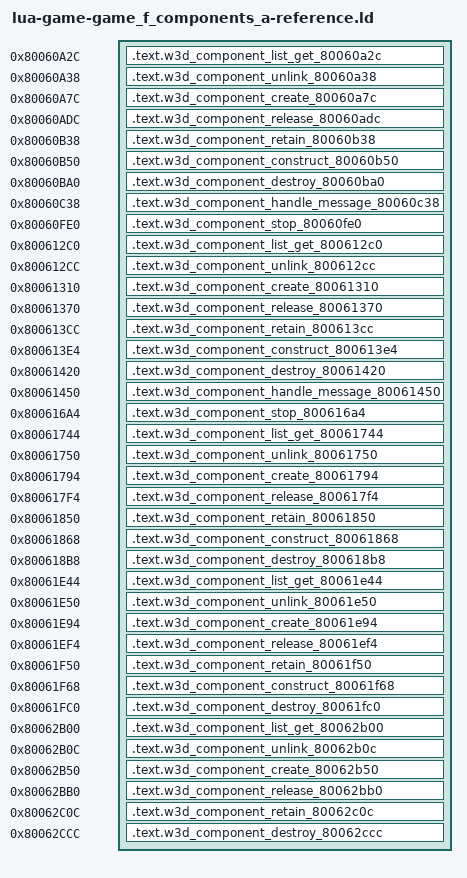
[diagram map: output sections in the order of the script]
/* Generated reference-only placements. All bodies are source-built. */
OUTPUT_FORMAT("elf32-powerpc")
OUTPUT_ARCH(powerpc)
ENTRY(w3d_component_list_get_80060a2c)
_SDA_BASE_ = 0x804b2540;
_SDA2_BASE_ = 0x804c2540;
w3d_actor_base_destroy = 0x80161050;
w3d_actor_base_initialize = 0x80161014;
w3d_base_construct_8002a914 = 0x8002a914;
w3d_base_construct_800ea180 = 0x800ea180;
w3d_base_destroy_8002a978 = 0x8002a978;
w3d_base_destroy_800ea324 = 0x800ea324;
w3d_base_destroy_8015ff2c = 0x8015ff2c;
w3d_base_handle_message_800ea62c = 0x800ea62c;
w3d_component_construct_80062c24 = 0x80062c24;
w3d_component_list_80360210 = 0x80360210;
w3d_component_list_80360240 = 0x80360240;
w3d_component_list_80360270 = 0x80360270;
w3d_component_list_803602a0 = 0x803602a0;
w3d_component_list_803602d0 = 0x803602d0;
w3d_component_start_80060cc0 = 0x80060cc0;
w3d_component_start_80061684 = 0x80061684;
w3d_component_vtable_8040ec08 = 0x8040ec08;
w3d_component_vtable_8040ec78 = 0x8040ec78;
w3d_component_vtable_8040ece8 = 0x8040ece8;
w3d_component_vtable_8040ed28 = 0x8040ed28;
w3d_component_vtable_8040ed80 = 0x8040ed80;
w3d_heap_allocate_entry_a = 0x801fe1d8;
w3d_owner_list_remove = 0x8020fd2c;
w3d_state_register = 0x8020fd04;
SECTIONS {
  .text.w3d_component_list_get_80060a2c 0x80060a2c : { *(.text.w3d_component_list_get_80060a2c) }
  .text.w3d_component_unlink_80060a38 0x80060a38 : { *(.text.w3d_component_unlink_80060a38) }
  .text.w3d_component_create_80060a7c 0x80060a7c : { *(.text.w3d_component_create_80060a7c) }
  .text.w3d_component_release_80060adc 0x80060adc : { *(.text.w3d_component_release_80060adc) }
  .text.w3d_component_retain_80060b38 0x80060b38 : { *(.text.w3d_component_retain_80060b38) }
  .text.w3d_component_construct_80060b50 0x80060b50 : { *(.text.w3d_component_construct_80060b50) }
  .text.w3d_component_destroy_80060ba0 0x80060ba0 : { *(.text.w3d_component_destroy_80060ba0) }
  .text.w3d_component_handle_message_80060c38 0x80060c38 : { *(.text.w3d_component_handle_message_80060c38) }
  .text.w3d_component_stop_80060fe0 0x80060fe0 : { *(.text.w3d_component_stop_80060fe0) }
  .text.w3d_component_list_get_800612c0 0x800612c0 : { *(.text.w3d_component_list_get_800612c0) }
  .text.w3d_component_unlink_800612cc 0x800612cc : { *(.text.w3d_component_unlink_800612cc) }
  .text.w3d_component_create_80061310 0x80061310 : { *(.text.w3d_component_create_80061310) }
  .text.w3d_component_release_80061370 0x80061370 : { *(.text.w3d_component_release_80061370) }
  .text.w3d_component_retain_800613cc 0x800613cc : { *(.text.w3d_component_retain_800613cc) }
  .text.w3d_component_construct_800613e4 0x800613e4 : { *(.text.w3d_component_construct_800613e4) }
  .text.w3d_component_destroy_80061420 0x80061420 : { *(.text.w3d_component_destroy_80061420) }
  .text.w3d_component_handle_message_80061450 0x80061450 : { *(.text.w3d_component_handle_message_80061450) }
  .text.w3d_component_stop_800616a4 0x800616a4 : { *(.text.w3d_component_stop_800616a4) }
  .text.w3d_component_list_get_80061744 0x80061744 : { *(.text.w3d_component_list_get_80061744) }
  .text.w3d_component_unlink_80061750 0x80061750 : { *(.text.w3d_component_unlink_80061750) }
  .text.w3d_component_create_80061794 0x80061794 : { *(.text.w3d_component_create_80061794) }
  .text.w3d_component_release_800617f4 0x800617f4 : { *(.text.w3d_component_release_800617f4) }
  .text.w3d_component_retain_80061850 0x80061850 : { *(.text.w3d_component_retain_80061850) }
  .text.w3d_component_construct_80061868 0x80061868 : { *(.text.w3d_component_construct_80061868) }
  .text.w3d_component_destroy_800618b8 0x800618b8 : { *(.text.w3d_component_destroy_800618b8) }
  .text.w3d_component_list_get_80061e44 0x80061e44 : { *(.text.w3d_component_list_get_80061e44) }
  .text.w3d_component_unlink_80061e50 0x80061e50 : { *(.text.w3d_component_unlink_80061e50) }
  .text.w3d_component_create_80061e94 0x80061e94 : { *(.text.w3d_component_create_80061e94) }
  .text.w3d_component_release_80061ef4 0x80061ef4 : { *(.text.w3d_component_release_80061ef4) }
  .text.w3d_component_retain_80061f50 0x80061f50 : { *(.text.w3d_component_retain_80061f50) }
  .text.w3d_component_construct_80061f68 0x80061f68 : { *(.text.w3d_component_construct_80061f68) }
  .text.w3d_component_destroy_80061fc0 0x80061fc0 : { *(.text.w3d_component_destroy_80061fc0) }
  .text.w3d_component_list_get_80062b00 0x80062b00 : { *(.text.w3d_component_list_get_80062b00) }
  .text.w3d_component_unlink_80062b0c 0x80062b0c : { *(.text.w3d_component_unlink_80062b0c) }
  .text.w3d_component_create_80062b50 0x80062b50 : { *(.text.w3d_component_create_80062b50) }
  .text.w3d_component_release_80062bb0 0x80062bb0 : { *(.text.w3d_component_release_80062bb0) }
  .text.w3d_component_retain_80062c0c 0x80062c0c : { *(.text.w3d_component_retain_80062c0c) }
  .text.w3d_component_destroy_80062ccc 0x80062ccc : { *(.text.w3d_component_destroy_80062ccc) }
  /DISCARD/ : { *(.text*) *(.rodata*) *(.data*) *(.bss*) *(.sdata*) *(.sbss*) *(.comment) }
}
